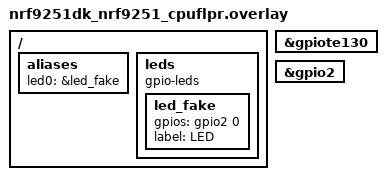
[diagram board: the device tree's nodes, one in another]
/*
 * Copyright (c) 2026 Nordic Semiconductor ASA
 *
 * SPDX-License-Identifier: LicenseRef-Nordic-5-Clause
 */

/ {
	aliases {
		led0 = &led_fake;
	};

	leds {
		compatible = "gpio-leds";

		led_fake: led_fake {
			gpios = <&gpio2 0 GPIO_ACTIVE_HIGH>;
			label = "LED";
		};
	};
};

&gpiote130 {
	status = "okay";
};

&gpio2 {
	status = "okay";
};
